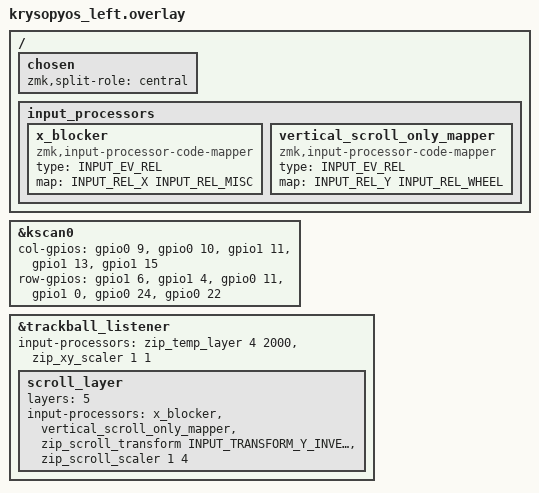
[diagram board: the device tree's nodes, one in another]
#include "krysopyos.dtsi"
#include <input/processors.dtsi>
#include <dt-bindings/zmk/input_transform.h>
#include <zephyr/dt-bindings/input/input-event-codes.h>

/ {
    chosen {
        zmk,split-role = "central";
    };

    input_processors {
        x_blocker: x_blocker {
            compatible = "zmk,input-processor-code-mapper";
            #input-processor-cells = <0>;
            type = <INPUT_EV_REL>;
            map = <INPUT_REL_X INPUT_REL_MISC>;
        };

        vertical_scroll_only_mapper: vertical_scroll_only_mapper {
            compatible = "zmk,input-processor-code-mapper";
            #input-processor-cells = <0>;
            type = <INPUT_EV_REL>;
            map = <INPUT_REL_Y INPUT_REL_WHEEL>;
        };
    };
};

&kscan0 {
    col-gpios
        = <&gpio0 9 GPIO_ACTIVE_HIGH>
        , <&gpio0 10 GPIO_ACTIVE_HIGH>
        , <&gpio1 11 GPIO_ACTIVE_HIGH>
        , <&gpio1 13 GPIO_ACTIVE_HIGH>
        , <&gpio1 15 GPIO_ACTIVE_HIGH>
        ;

    row-gpios
        = <&gpio1 6 (GPIO_ACTIVE_HIGH | GPIO_PULL_DOWN)>
        , <&gpio1 4 (GPIO_ACTIVE_HIGH | GPIO_PULL_DOWN)>
        , <&gpio0 11 (GPIO_ACTIVE_HIGH | GPIO_PULL_DOWN)>
        , <&gpio1 0 (GPIO_ACTIVE_HIGH | GPIO_PULL_DOWN)>
        , <&gpio0 24 (GPIO_ACTIVE_HIGH | GPIO_PULL_DOWN)>
        , <&gpio0 22 (GPIO_ACTIVE_HIGH | GPIO_PULL_DOWN)>
        ;
};

&trackball_listener {
    status = "okay";
    input-processors = <&zip_temp_layer 4 2000 &zip_xy_scaler 1 1>;

    scroll_layer {
        layers = <5>;
        input-processors = <&x_blocker &vertical_scroll_only_mapper &zip_scroll_transform INPUT_TRANSFORM_Y_INVERT &zip_scroll_scaler 1 4>;
    };
};
